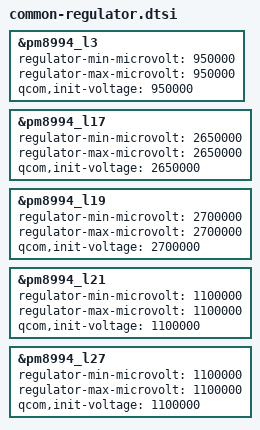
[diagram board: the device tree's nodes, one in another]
&pm8994_l3 {
	regulator-min-microvolt = <950000>;
	regulator-max-microvolt = <950000>;
	qcom,init-voltage = <950000>;
};

&pm8994_l17 {
	regulator-min-microvolt = <2650000>;
	regulator-max-microvolt = <2650000>;
	qcom,init-voltage = <2650000>;
};

&pm8994_l19 {
	regulator-min-microvolt = <2700000>;
	regulator-max-microvolt = <2700000>;
	qcom,init-voltage = <2700000>;
};

&pm8994_l21 {
	regulator-min-microvolt = <1100000>;
	regulator-max-microvolt = <1100000>;
	qcom,init-voltage = <1100000>;
};

&pm8994_l27 {
	regulator-min-microvolt = <1100000>;
	regulator-max-microvolt = <1100000>;
	qcom,init-voltage = <1100000>;
};
